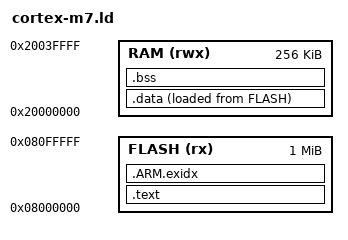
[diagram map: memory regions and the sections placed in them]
/* Linker script for Cortex-M7 */
MEMORY
{
  FLASH (rx) : ORIGIN = 0x08000000, LENGTH = 1024K
  RAM (rwx)  : ORIGIN = 0x20000000, LENGTH = 256K
}

SECTIONS
{
  .text :
  {
    KEEP(*(.isr_vector))
    *(.text*)
    *(.rodata*)
    . = ALIGN(4);
  } > FLASH

  .data :
  {
    . = ALIGN(4);
    _sdata = .;
    *(.data*)
    . = ALIGN(4);
    _edata = .;
  } > RAM AT > FLASH

  .bss :
  {
    . = ALIGN(4);
    _sbss = .;
    *(.bss*)
    *(COMMON)
    . = ALIGN(4);
    _ebss = .;
  } > RAM

  /* For semihosting */
  .ARM.exidx :
  {
    *(.ARM.exidx*)
  } > FLASH
}

/* Minimal vector table for Cortex-M */
PROVIDE(_stack_top = ORIGIN(RAM) + LENGTH(RAM));
